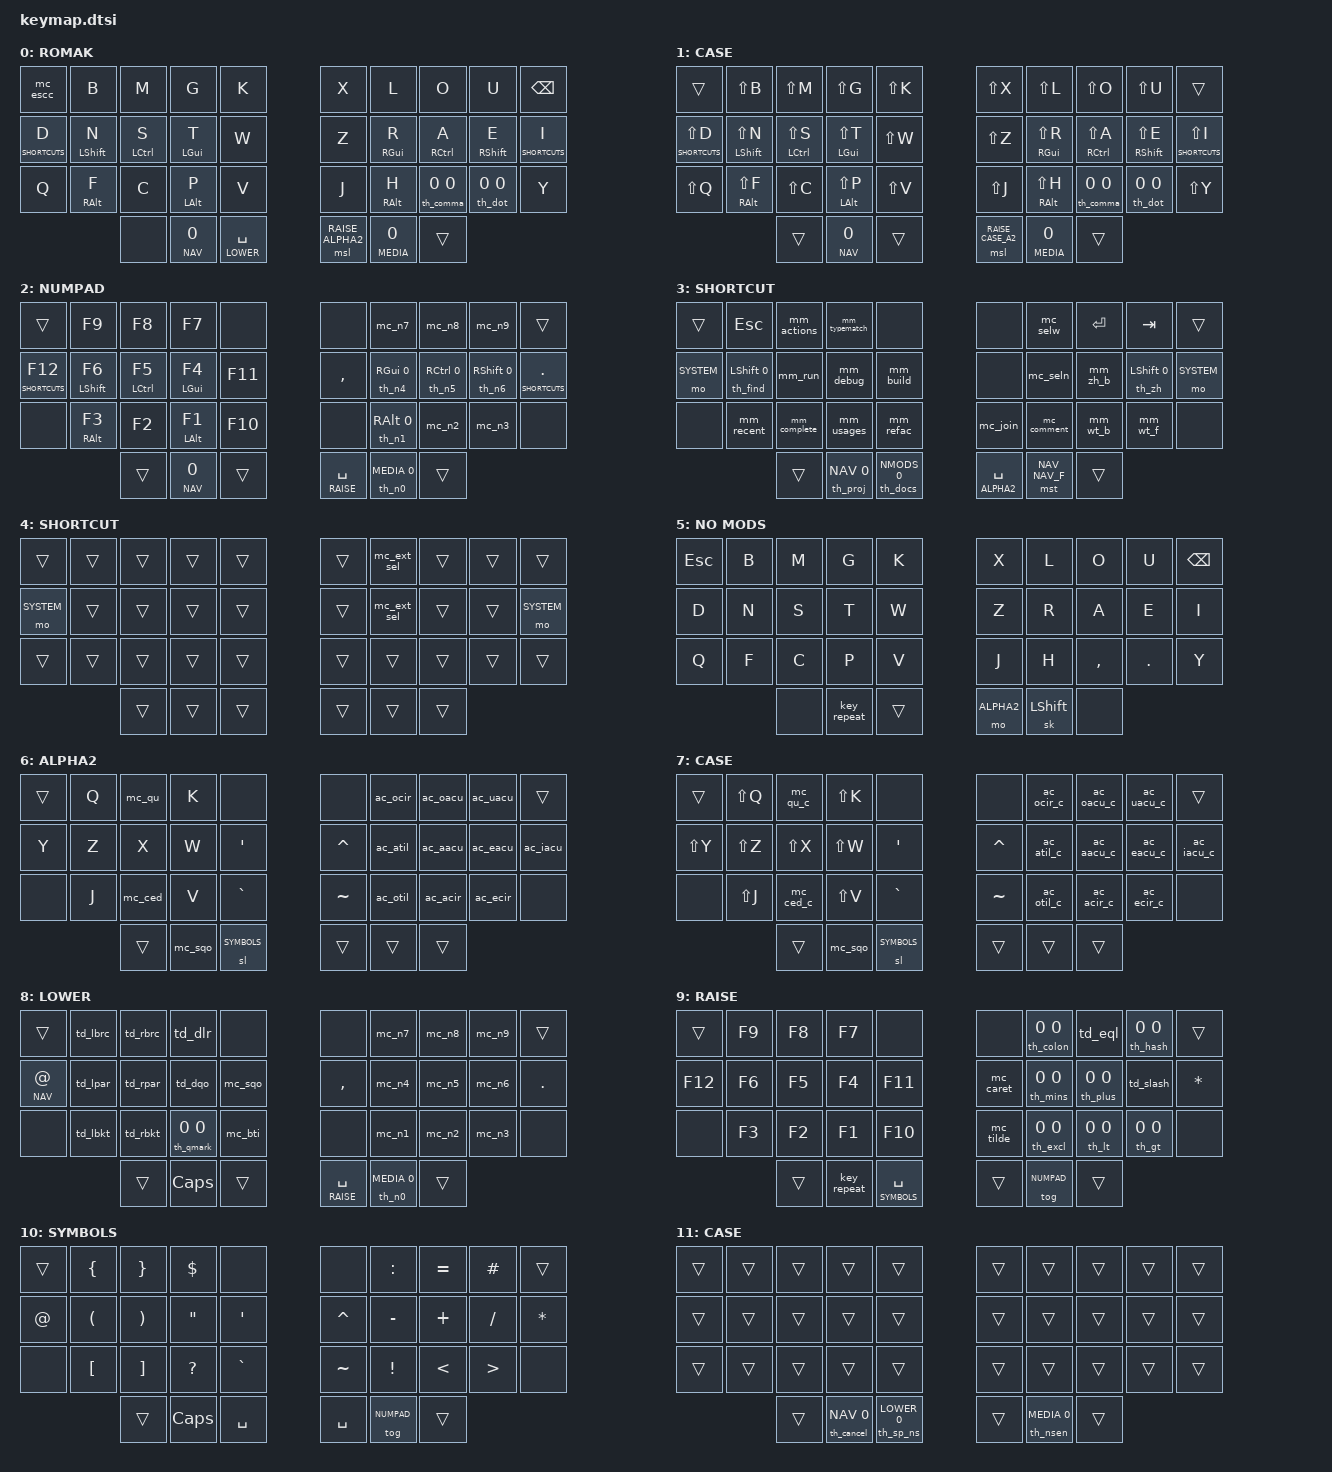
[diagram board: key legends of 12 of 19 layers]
/*
*
* Copyright (c) 2022 Rafael Romão
* SPDX-License-Identifier: MIT
*
*/

#include "keycodes.h"
#include "config.dtsi"

#include "../features/behaviors.dtsi"
#include "../features/accents.dtsi"
#include "../features/thumbs.dtsi"
#include "../features/swapper.dtsi"
#include "../features/symbols.dtsi"
#include "../features/shortcuts.dtsi"
#include "../features/combos.dtsi"
#include "../features/leader.dtsi"
#if __has_include("../secret.dtsi")
#include "../secret.dtsi"
#endif

/ {
        keymap {
                compatible = "zmk,keymap";
                default_layer {
                     label = "ROMAK";
                     bindings = <
   &mc_escc            &kp B               &kp M               &kp G               &kp K               &kp X               &kp L               &kp O               &kp U               &kp BSPC
   &lt SHORTCUTS D     &mt LSHFT N         &mt LCTRL S         &mt LGUI T          &kp W               &kp Z               &mt RGUI R          &mt RCTRL A         &mt RSHFT E         &lt SHORTCUTS I 
   &kp Q               &mt RALT F          &kp C               &mt LALT P          &kp V               &kp J               &mt RALT H          &th_comma 0 0       &th_dot 0 0         &kp Y
                                           &none               &ht_repeat NAV 0    &lt LOWER SPACE     &msl RAISE ALPHA2   &ht_magic MEDIA 0   &trans
                        >;
                   };
                capsword_layer {
                     label = "CASE";
                     bindings = <
   &trans              &kp LS(B)           &kp LS(M)           &kp LS(G)           &kp LS(K)           &kp LS(X)           &kp LS(L)           &kp LS(O)           &kp LS(U)           &trans
   &lt SHORTCUTS LS(D) &mt LSHFT LS(N)     &mt LCTRL LS(S)     &mt LGUI LS(T)      &kp LS(W)           &kp LS(Z)           &mt RGUI LS(R)      &mt RCTRL LS(A)     &mt RSHFT LS(E)     &lt SHORTCUTS LS(I) 
   &kp LS(Q)           &mt RALT LS(F)      &kp LS(C)           &mt LALT LS(P)      &kp LS(V)           &kp LS(J)           &mt RALT LS(H)      &th_comma 0 0       &th_dot 0 0         &kp LS(Y)
                                           &trans              &ht_repeat NAV 0    &trans              &msl RAISE CASE_A2  &ht_magic MEDIA 0   &trans
                        >;
                };
                numpad_layer {
                     label = "NUMPAD";
                     bindings = <
   &trans              &kp F9              &kp F8              &kp F7              &none               &none               &mc_n7              &mc_n8              &mc_n9              &trans
   &lt SHORTCUTS F12   &mt LSHFT F6        &mt LCTRL F5        &mt LGUI F4         &kp F11             &kp COMMA           &th_n4 RGUI 0       &th_n5 RCTRL 0      &th_n6 RSHFT 0      &lt SHORTCUTS DOT 
   &none               &mt RALT F3         &kp F2              &mt LALT F1         &kp F10             &none               &th_n1 RALT 0       &mc_n2              &mc_n3              &none
                                           &trans              &ht_repeat NAV 0    &trans              &lt RAISE SPACE     &th_n0 MEDIA 0      &trans
                           >;
                };
                shortcuts_layer {
                     label = "SHORTCUT";
                     bindings = <
   &trans              &kp ESC             &mm_actions         &mm_typematch       &none               &none               &mc_selw            &kp ENTER           &kp TAB             &trans    
   &mo SYSTEM          &th_find LSHFT 0    &mm_run             &mm_debug           &mm_build           &none               &mc_seln            &mm_zh_b            &th_zh LSHFT 0      &mo SYSTEM
   &none               &mm_recent          &mm_complete        &mm_usages          &mm_refac           &mc_join            &mc_comment         &mm_wt_b            &mm_wt_f            &none
                                           &trans              &th_proj NAV 0      &th_docs NMODS 0    &lt ALPHA2 SPACE    &mst NAV NAV_F      &trans
                           >;
                };
                shortcuts_extension_layer {
                     label = "SHORTCUT";
                     bindings = <
   &trans              &trans              &trans              &trans              &trans              &trans              &mc_ext_sel         &trans              &trans              &trans    
   &mo SYSTEM          &trans              &trans              &trans              &trans              &trans              &mc_ext_sel         &trans              &trans              &mo SYSTEM  
   &trans              &trans              &trans              &trans              &trans              &trans              &trans              &trans              &trans              &trans 
                                           &trans              &trans              &trans              &trans              &trans              &trans
                           >;
                };
                no_mods_layer {
                     label = "NO MODS";
                     bindings = <
   &kp ESC            &kp B                &kp M               &kp G               &kp K               &kp X               &kp L               &kp O               &kp U               &kp BSPC
   &kp D              &kp N                &kp S               &kp T               &kp W               &kp Z               &kp R               &kp A               &kp E               &kp I 
   &kp Q              &kp F                &kp C               &kp P               &kp V               &kp J               &kp H               &kp COMMA           &kp DOT             &kp Y
                                           &none               &key_repeat         &trans              &mo ALPHA2          &sk LSHFT           &none
                           >;
                };
                alpha2_layer {
                     label = "ALPHA2";
                     bindings = <
   &trans              &kp Q               &mc_qu              &kp K               &none               &none               &ac_ocir            &ac_oacu            &ac_uacu            &trans
   &kp Y               &kp Z               &kp X               &kp W               &kp SQT             &kp CARET           &ac_atil            &ac_aacu            &ac_eacu            &ac_iacu 
   &none               &kp J               &mc_ced             &kp V               &kp GRAVE           &kp TILDE           &ac_otil            &ac_acir            &ac_ecir            &none
                                           &trans              &mc_sqo             &sl SYMBOLS         &trans              &trans              &trans
                           >;
                };
                case_alpha2_layer {
                     label = "CASE";
                     bindings = <
   &trans              &kp LS(Q)           &mc_qu_c            &kp LS(K)           &none               &none               &ac_ocir_c          &ac_oacu_c          &ac_uacu_c          &trans
   &kp LS(Y)           &kp LS(Z)           &kp LS(X)           &kp LS(W)           &kp SQT             &kp CARET           &ac_atil_c          &ac_aacu_c          &ac_eacu_c          &ac_iacu_c 
   &none               &kp LS(J)           &mc_ced_c           &kp LS(V)           &kp GRAVE           &kp TILDE           &ac_otil_c          &ac_acir_c          &ac_ecir_c          &none
                                           &trans              &mc_sqo             &sl SYMBOLS         &trans              &trans              &trans
                           >;
                };
                lower_layer {
                     label = "LOWER";
                     bindings = <
   &trans              &td_lbrc            &td_rbrc            &td_dlr             &none               &none               &mc_n7              &mc_n8              &mc_n9              &trans
   &lt NAV AT          &td_lpar            &td_rpar            &td_dqo             &mc_sqo             &kp COMMA           &mc_n4              &mc_n5              &mc_n6              &kp DOT  
   &none               &td_lbkt            &td_rbkt            &th_qmark 0 0       &mc_bti             &none               &mc_n1              &mc_n2              &mc_n3              &none
                                           &trans              &kp CAPSLOCK        &trans              &lt RAISE SPACE     &th_n0 MEDIA 0      &trans
                           >;
                };
                raise_layer {
                     label = "RAISE";
                     bindings = <
   &trans              &kp F9              &kp F8              &kp F7              &none               &none               &th_colon 0 0       &td_eql             &th_hash 0 0        &trans
   &kp F12             &kp F6              &kp F5              &kp F4              &kp F11             &mc_caret           &th_mins 0 0        &th_plus 0 0        &td_slash           &kp STAR  
   &none               &kp F3              &kp F2              &kp F1              &kp F10             &mc_tilde           &th_excl 0 0        &th_lt 0 0          &th_gt 0 0          &none
                                           &trans              &key_repeat         &lt SYMBOLS SPACE   &trans              &tog NUMPAD         &trans       
                           >;
                };
                symbols_layer {
                     label = "SYMBOLS";
                     bindings = <
   &trans              &kp LBRC            &kp RBRC            &kp DOLLAR          &none               &none               &kp COLON           &kp EQUAL           &kp HASH            &trans
   &kp AT              &kp LPAR            &kp RPAR            &kp DQT             &kp SQT             &kp CARET           &kp MINUS           &kp PLUS            &kp SLASH           &kp STAR 
   &none               &kp LBKT            &kp RBKT            &kp QMARK           &kp GRAVE           &kp TILDE           &kp EXCL            &kp LT              &kp GT              &none
                                           &trans              &kp CAPSLOCK        &kp SPACE           &kp SPACE           &tog NUMPAD         &trans
                           >;
                };
                sentence_case_layer {
                     label = "CASE";
                     bindings = <
   &trans              &trans              &trans              &trans              &trans              &trans              &trans              &trans              &trans              &trans    
   &trans              &trans              &trans              &trans              &trans              &trans              &trans              &trans              &trans              &trans  
   &trans              &trans              &trans              &trans              &trans              &trans              &trans              &trans              &trans              &trans 
                                           &trans              &th_cancel NAV 0    &th_sp_ns LOWER 0   &trans              &th_nsen MEDIA 0    &trans
                           >;
                };
                sentence_case_ext1_layer {
                     label = "CASE";
                     bindings = <
   &trans              &kp LS(B)           &kp LS(M)           &kp LS(G)           &kp LS(K)           &kp LS(X)           &kp LS(L)           &kp LS(O)           &kp LS(U)           &trans
   &lt SHORTCUTS LS(D) &mt LSHFT LS(N)     &mt LCTRL LS(S)     &mt LGUI LS(T)      &kp LS(W)           &kp LS(Z)           &mt RGUI LS(R)      &mt RCTRL LS(A)     &mt RSHFT LS(E)     &lt SHORTCUTS LS(I) 
   &kp LS(Q)           &mt RALT LS(F)      &kp LS(C)           &mt LALT LS(P)      &kp LS(V)           &kp LS(J)           &mt LALT LS(H)      &th_comma 0 0       &th_dot 0 0         &kp LS(Y)
                                           &trans              &th_cancel NAV 0    &th_sp_ns LOWER 0   &msl RAISE SEN_E2   &th_nsen MEDIA 0    &trans
                           >;
                };
                sentence_case_ext2_layer {
                     label = "CASE";
                     bindings = <
   &trans              &kp LS(Q)           &mc_qu_c            &kp LS(K)           &none               &none               &ac_ocir_c          &ac_oacu_c          &ac_uacu_c          &trans
   &kp LS(Y)           &kp LS(Z)           &kp LS(X)           &kp LS(W)           &kp SQT             &kp CARET           &ac_atil_c          &ac_aacu_c          &ac_eacu_c          &ac_iacu_c 
   &none               &kp LS(J)           &mc_ced_c           &kp LS(V)           &kp GRAVE           &kp TILDE           &ac_otil_c          &ac_acir_c          &ac_ecir_c          &none
                                           &trans              &th_cancel NAV 0    &th_sp_ns LOWER 0   &none               &th_nsen MEDIA 0    &trans
                           >;
                };
                navigation_layer {
                     label = "NAV";
                     bindings = <
   &trans              &kp ESC             &mc_meh_m           &mc_meh_g           &none               &none               &kp INS             &kp ENTER           &kp TAB             &trans
   &mc_meh_d           &kp LSHIFT          &kp LCTRL           &kp LGUI            &none               &none               &kp LEFT            &kp DOWN            &kp UP              &kp RIGHT
   &none               &kp RALT            &mc_meh_c           &kp LALT            &none               &none               &kp DEL             &kp HOME            &kp END             &none
                                           &trans              &trans              &trans              &kp SPACE           &mo MEDIA           &trans
                        >;
                };
                media_layer {
                     label = "MEDIA";
                     bindings = <
   &trans              &kp ESC             &none               &none               &none               &none               &mc_hyp_l           &kp ENTER           &kp TAB             &trans
   &none               &none               &none               &none               &none               &none               &mc_hyp_r           &kp C_VOL_DN        &kp C_VOL_UP        &kp C_MUTE
   &none               &none               &none               &none               &none               &none               &kp C_PP            &kp C_PREV          &kp C_NEXT          &none
                                           &trans              &mo NAV_F           &kp SPACE           &trans              &trans              &trans
                           >;
                };
                fixed_navigation_layer {
                     label = "NAV";
                     bindings = <
   &trans              &kp ESC             &mc_meh_m           &mc_meh_g           &none               &none               &kp INS             &kp ENTER           &kp TAB             &trans
   &mc_meh_d           &kp LSHIFT          &kp LCTRL           &kp LGUI            &none               &none               &kp LEFT            &kp DOWN            &kp UP              &kp RIGHT
   &none               &kp RALT            &mc_meh_c           &kp LALT            &none               &none               &kp DEL             &kp HOME            &kp END             &none
                                           &trans              &trans              &kp SPACE           &kp SPACE           &to ALPHA1          &trans
                           >;
                };
                lock_layer {
                     label = "LOCK";
                     bindings = <
   &none               &none               &none               &none               &none               &none               &none               &none               &none               &none    
   &trans              &none               &none               &none               &none               &none               &none               &none               &none               &trans  
   &none               &none               &none               &none               &none               &none               &none               &none               &none               &none 
                                           &none               &none               &none               &none               &none               &none
                        >;
                };
                system_layer {
                     label = "SYSTEM";
                     bindings = <
   &trans              &none               &none               &bootloader         &none               &none               &bootloader         &none               &none                &trans 
   &none               &none               &none               &none               &none               &none               &kp LC(LG(Q))       &kp C_SLEEP         &tog LOCK_KB         &none      
   &none               &none               &none               &sys_reset          &none               &none               &sys_reset          &bt BT_PRV          &bt BT_NXT           &none
                                           &trans              &trans              &trans              &trans              &trans              &trans
                        >;
                };
        };
};
